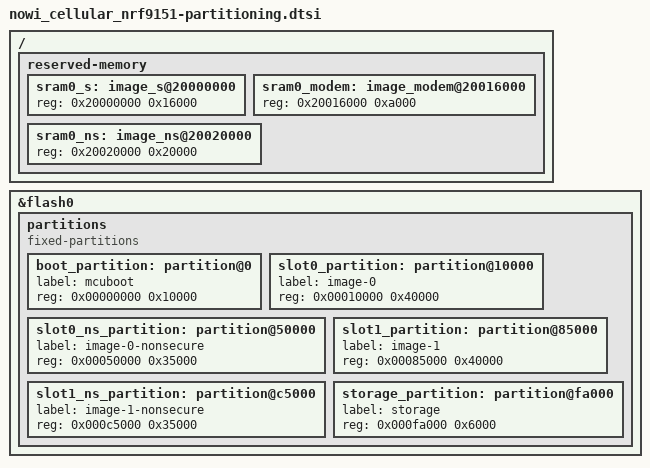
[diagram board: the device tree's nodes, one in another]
/*
 * Copyright (c) 2021 Nordic Semiconductor ASA
 *
 * SPDX-License-Identifier: LicenseRef-Nordic-5-Clause
 */

// / {
// 	chosen {
// 		zephyr,code-partition = &slot0_ns_partition;
// 		nordic,pm-ext-flash = &flash0;
// 	};
// };

&flash0 {
	partitions {
		compatible = "fixed-partitions";
		#address-cells = <1>;
		#size-cells = <1>;

		boot_partition: partition@0 {
			label = "mcuboot";
			reg = <0x00000000 0x10000>;
		};

		slot0_partition: partition@10000 {
			label = "image-0";
			reg = <0x00010000 0x40000>;
		};

		slot0_ns_partition: partition@50000 {
			label = "image-0-nonsecure";
			reg = <0x00050000 0x35000>;
		};

		slot1_partition: partition@85000 {
			label = "image-1";
			reg = <0x00085000 0x40000>;
		};

		slot1_ns_partition: partition@c5000 {
			label = "image-1-nonsecure";
			reg = <0x000c5000 0x35000>;
		};

		storage_partition: partition@fa000 {
			label = "storage";
			reg = <0x000fa000 0x6000>;
		};
	};
};

/* Default SRAM planning when building with ARM TrustZone-M support */
/ {
	reserved-memory {
		#address-cells = <1>;
		#size-cells = <1>;
		ranges;

		sram0_s: image_s@20000000 {
			reg = <0x20000000 0x16000>;
		};

		sram0_modem: image_modem@20016000 {
			reg = <0x20016000 0xa000>;
		};

		sram0_ns: image_ns@20020000 {
			reg = <0x20020000 0x20000>;
		};
	};
};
